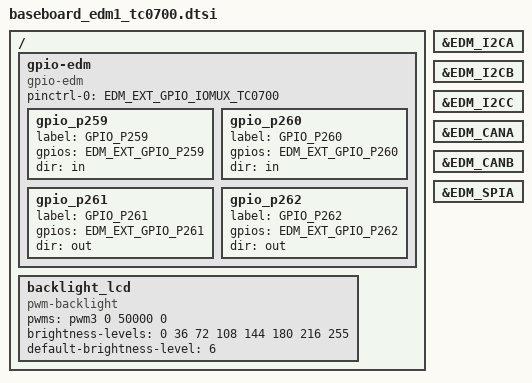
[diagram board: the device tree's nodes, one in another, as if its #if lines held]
/*
 * Copyright 2018 Technexion Ltd.
 *
 * Author: Tapani Utriainen <tapani@technexion.com>
 *         Richard Hu <richard.hu@technexion.com>
 *
 * This program is free software; you can redistribute it and/or modify
 * it under the terms of the GNU General Public License version 2 as
 * published by the Free Software Foundation.
 *
 */

#include <tnmacro.h>

/ {
	gpio-edm {
		compatible = "gpio-edm";
/* custom GPIO may be from GPIO expander on CPU module */
#ifdef EDM_EXT_GPIO_IOMUX_TC0700
		pinctrl-names = "default";
		pinctrl-0 = <EDM_EXT_GPIO_IOMUX_TC0700>;
#endif
		gpio_p259 {
			label = "GPIO_P259";
			gpios = <&EDM_EXT_GPIO_P259 GPIO_ACTIVE_HIGH>;
			dir   = "in";
		};

		gpio_p260 {
			label = "GPIO_P260";
			gpios = <&EDM_EXT_GPIO_P260 GPIO_ACTIVE_HIGH>;
			dir   = "in";
		};

		gpio_p261 {
			label = "GPIO_P261";
			gpios = <&EDM_EXT_GPIO_P261 GPIO_ACTIVE_HIGH>;
			dir   = "out";
		};

		gpio_p262 {
			label = "GPIO_P262";
			gpios = <&EDM_EXT_GPIO_P262 GPIO_ACTIVE_HIGH>;
			dir   = "out";
		};
	};

	backlight_lcd {
		compatible = "pwm-backlight";
		pwms = <&pwm3 0 50000 0>;
		brightness-levels = <0 36 72 108 144 180 216 255>;
		default-brightness-level = <6>;
	};	

};

&EDM_I2CA {
	status = "okay";
};

&EDM_I2CB {
	status = "okay";
};

&EDM_I2CC {
	status = "okay";
};

&EDM_CANA {
	status = "okay";
};

&EDM_CANB {
	status = "okay";
};

&EDM_SPIA {
	status = "okay";
};
